VERSION ""

NS_ :

BU_: Motor Controller
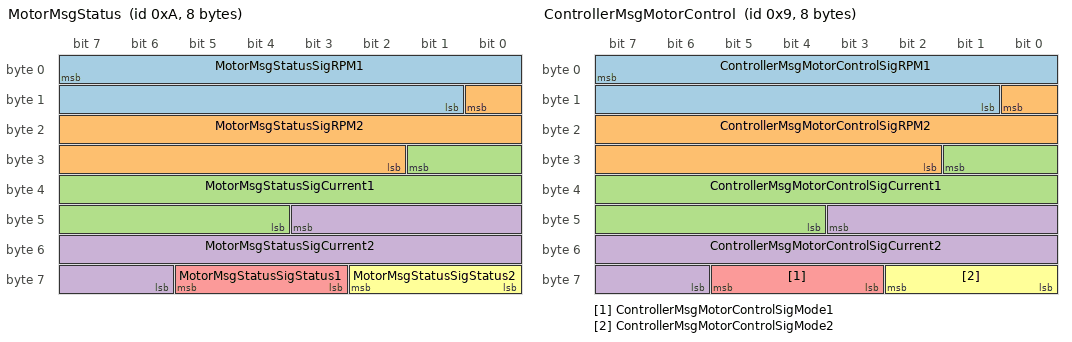
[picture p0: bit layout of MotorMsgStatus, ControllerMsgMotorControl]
BO_ 10 MotorMsgStatus: 8 Motor
   SG_ MotorMsgStatusSigRPM1 : 7|15@0- (1,0) [-15000|15000] "RPM" Controller
   SG_ MotorMsgStatusSigRPM2 : 8|15@0- (1,0) [-15000|15000] "RPM" Controller
   SG_ MotorMsgStatusSigCurrent1 : 25|14@0- (1,0) [-6000|6000] "mA" Controller
   SG_ MotorMsgStatusSigCurrent2 : 43|14@0- (1,0) [-6000|6000] "mA" Controller
   SG_ MotorMsgStatusSigStatus1 : 61|3@0+ (1,0) [0|7] "" Controller
   SG_ MotorMsgStatusSigStatus2 : 58|3@0+ (1,0) [0|7] "" Controller

BO_ 9 ControllerMsgMotorControl: 8 Controller
   SG_ ControllerMsgMotorControlSigRPM1 : 7|15@0- (1,0) [-15000|15000] "RPM" Motor
   SG_ ControllerMsgMotorControlSigRPM2 : 8|15@0- (1,0) [-15000|15000] "RPM" Motor
   SG_ ControllerMsgMotorControlSigCurrent1 : 25|14@0- (1,0) [-6000|6000] "mA" Motor
   SG_ ControllerMsgMotorControlSigCurrent2 : 43|14@0- (1,0) [-6000|6000] "mA" Motor
   SG_ ControllerMsgMotorControlSigMode1 : 61|3@0+ (1,0) [0|7] "" Motor
   SG_ ControllerMsgMotorControlSigMode2 : 58|3@0+ (1,0) [0|7] "" Motor

BA_DEF_  "BusType" STRING ;
BA_DEF_ BO_  "GenMsgSendType" ENUM  "cyclic","NotUsed","IfActive","NotUsed","NotUsed","NotUsed","NotUsed","NotUsed","noMsgSendType";
BA_DEF_ BO_  "GenMsgCycleTime" INT 0 1000;
BA_DEF_DEF_  "BusType" "CAN";
BA_DEF_DEF_  "GenMsgSendType" "noMsgSendType";
BA_DEF_DEF_  "GenMsgCycleTime" 0;
BA_ "GenMsgCycleTime" BO_ 9 100;
BA_ "GenMsgSendType" BO_ 9 0;

VAL_ 10 MotorMsgStatusSigStatus1 0 "UNKNOWN" 1 "RUN" 2 "COAST" 3 "BRAKE" 4 "SHORT_TO_GROUND" 5 "SHORT_TO_VCC" 6 "OPEN_LOAD" 7 "THERMAL_SHUTDOWN";
VAL_ 10 MotorMsgStatusSigStatus2 0 "UNKNOWN" 1 "RUN" 2 "COAST" 3 "BRAKE" 4 "SHORT_TO_GROUND" 5 "SHORT_TO_VCC" 6 "OPEN_LOAD" 7 "THERMAL_SHUTDOWN";

VAL_ 9 ControllerMsgMotorControlSigMode1 0 "UNKNOWN" 1 "RUN" 2 "COAST" 3 "BRAKE";
VAL_ 9 ControllerMsgMotorControlSigMode2 0 "UNKNOWN" 1 "RUN" 2 "COAST" 3 "BRAKE";
